# S1C31D01 register map
Vendor: Epson; Series: S1C31D01; File version: 1.00
CPU: CM0PLUS r0p1, little endian, MPU, no FPU, VTOR, 2 interrupt priority bits
Registers are 16-bit, read-write, reset 0x0 unless marked. A register's access mark holds for its fields unless they carry their own. Offsets are from the block's base; [hi:lo] are bit positions; {n}, {i} and the like mark numbered series; 'fields as' and 'values as' point back to an identical list.

## FLASHC — Flash controller
Base 0x400001B0
0x00 WAIT reset 0x1 — Flash Read Cycle Register
  [1:0] RDWAIT — RdCycle Number of cycles (can be write protected)

## UPMUX — Universal port multiplexer control
Base 0x40000300
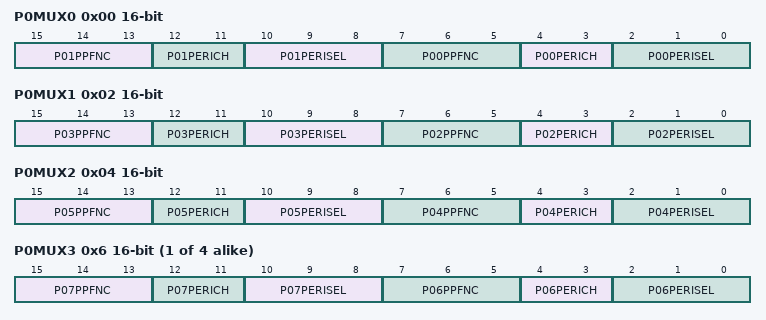
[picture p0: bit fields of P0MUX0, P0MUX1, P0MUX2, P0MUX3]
0x00 P0MUX0 — P00_01 Universal Port Multiplexer Setting Register
  [15:13] P01PPFNC — Assign pin function
  [12:11] P01PERICH — Assign Peripheral channel
  [10:8] P01PERISEL — Assign peripheral
  [7:5] P00PPFNC — Assign pin function
  [4:3] P00PERICH — Assign Peripheral channel
  [2:0] P00PERISEL — Assign peripheral
0x02 P0MUX1 — P02_03 Universal Port Multiplexer Setting Register
  [15:13] P03PPFNC — Assign pin function
  [12:11] P03PERICH — Assign peripheral channel
  [10:8] P03PERISEL — Assign peripheral
  [7:5] P02PPFNC — Assign pin function
  [4:3] P02PERICH — Assign Peripheral channel
  [2:0] P02PERISEL — Assign peripheral
0x04 P0MUX2 — P04_05 Universal Port Multiplexer Setting Register
  [15:13] P05PPFNC — Assign pin function
  [12:11] P05PERICH — Assign Peripheral channel
  [10:8] P05PERISEL — Assign peripheral
  [7:5] P04PPFNC — Assign pin function
  [4:3] P04PERICH — Assign Peripheral channel
  [2:0] P04PERISEL — Assign peripheral
{0x6+8i} P{i}MUX3 (i=0..3) — P{10i+6:02}_{10i+7:02} Universal Port Multiplexer Setting Register
  [15:13] P{10i+7:02}PPFNC — Assign pin function
  [12:11] P{10i+7:02}PERICH — Assign Peripheral channel
  [10:8] P{10i+7:02}PERISEL — Assign peripheral
  [7:5] P{10i+6:02}PPFNC — Assign pin function
  [4:3] P{10i+6:02}PERICH — Assign Peripheral channel
  [2:0] P{10i+6:02}PERISEL — Assign peripheral
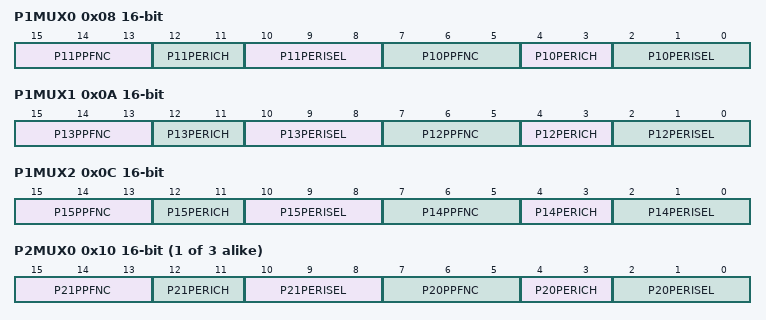
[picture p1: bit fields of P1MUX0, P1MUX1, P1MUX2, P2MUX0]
0x08 P1MUX0 — P10_11 Universal Port Multiplexer Setting Register
  [15:13] P11PPFNC — Assign pin function
  [12:11] P11PERICH — Assign Peripheral channel
  [10:8] P11PERISEL — Assign peripheral
  [7:5] P10PPFNC — Assign pin function
  [4:3] P10PERICH — Assign Peripheral channel
  [2:0] P10PERISEL — Assign peripheral
0x0A P1MUX1 — P12_13 Universal Port Multiplexer Setting Register
  [15:13] P13PPFNC — Assign pin function
  [12:11] P13PERICH — Assign Peripheral channel
  [10:8] P13PERISEL — Assign peripheral
  [7:5] P12PPFNC — Assign pin function
  [4:3] P12PERICH — Assign Peripheral channel
  [2:0] P12PERISEL — Assign peripheral
0x0C P1MUX2 — P14_15 Universal Port Multiplexer Setting Register
  [15:13] P15PPFNC — Assign pin function
  [12:11] P15PERICH — Assign Peripheral channel
  [10:8] P15PERISEL — Assign peripheral
  [7:5] P14PPFNC — Assign pin function
  [4:3] P14PERICH — Assign Peripheral channel
  [2:0] P14PERISEL — Assign peripheral
{0x10+2i} P2MUX{i} (i=0..2) — P{2i+20}_{2i+21} Universal Port Multiplexer Setting Register
  [15:13] P{2i+21}PPFNC — Assign pin function
  [12:11] P{2i+21}PERICH — Assign peripheral channel
  [10:8] P{2i+21}PERISEL — Assign peripheral
  [7:5] P{2i+20}PPFNC — Assign pin function
  [4:3] P{2i+20}PERICH — Assign peripheral channel
  [2:0] P{2i+20}PERISEL — Assign peripheral
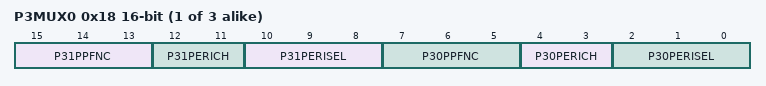
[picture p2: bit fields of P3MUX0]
{0x18+2i} P3MUX{i} (i=0..2) — P{2i+30}_{2i+31} Universal Port Multiplexer Setting Register
  [15:13] P{2i+31}PPFNC — Assign pin function
  [12:11] P{2i+31}PERICH — Assign peripheral channel
  [10:8] P{2i+31}PERISEL — Assign peripheral
  [7:5] P{2i+30}PPFNC — Assign pin function
  [4:3] P{2i+30}PERICH — Assign peripheral channel
  [2:0] P{2i+30}PERISEL — Assign peripheral

## UART3_0 — UART3 channel 0 control
Base 0x40000380
Same registers: UART3_1 0x40000600, UART3_2 0x40000620
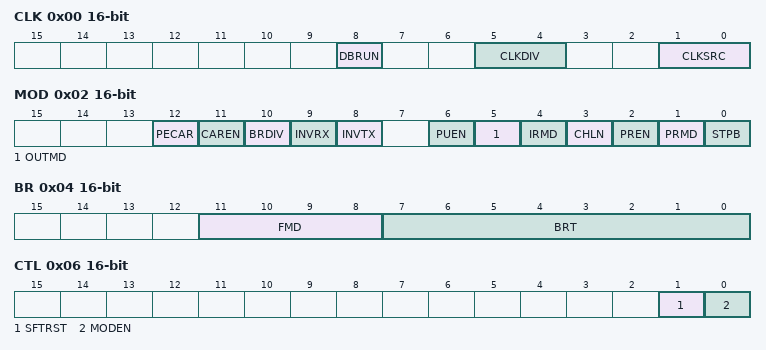
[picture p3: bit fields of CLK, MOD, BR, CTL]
0x00 CLK — Clock Control Register
  [8] DBRUN — Enable clock on debug mode
    0=DISABLE; 1=ENABLE
  [5:4] CLKDIV — Clock division select
  [1:0] CLKSRC — Clock source select (can be write protected)
    0=IOSC; 1=OSC1; 2=OSC3; 3=EXOSC
0x02 MOD — Mode Register
  [12] PECAR — Select carrier modulation
  [11] CAREN — Carrier modulation enable
  [10] BRDIV — Baud Rate Division ratio
    0=DIV_1_16 (Ratio 1 over 16); 1=DIV_1_4 (Ration 1 over 4)
  [9] INVRX — Invert receive signal
    0=DISABLE (Disable input inverting function); 1=ENABLE (Enable input inverting function)
  [8] INVTX — Invert transmit signal
    0=DISABLE (Disable output inverting function); 1=ENABLE (Enable output inverting function)
  [6] PUEN — USIN pullup enable
    0=DISABLE (Disable pull-up); 1=ENABLE (Enable pull-up)
  [5] OUTMD — Output mode select
    0=PUSH_PULL (Push-pull output); 1=OPEN_DRAIN (Open-drain output)
  [4] IRMD — IrDA mode select
    0=DISABLE (Disable IrDA interface function); 1=ENABLE (Enable IrDA interface function)
  [3] CHLN — Character length
    0=7_BIT (7 bits); 1=8_BIT (8 bits)
  [2] PREN — Parity enable
    0=DISABLE (Disable parity function); 1=ENABLE (Enable parity function)
  [1] PRMD — Parity mode select
    0=EVEN (Even parity); 1=ODD (Odd parity)
  [0] STPB — Stop bit select
    0=1_BIT; 1=2_BIT (2 bits)
0x04 BR — Baud Rate Register
  [11:8] FMD — Fine mode control
  [7:0] BRT — Baud rate setting
0x06 CTL — Control Register
  [1] SFTRST write-1-sets — Soft reset
    on write: 0=NON (No effect); 1=RESET (Issue software reset) | on read: 0=STOPPED (Software reset has finished (During normal operation)); 1=RUNNING (Software reset is executing)
  [0] MODEN — UART3 enable
    0=DISABLE (Disable UART2 operations (The operating clock is stopped)); 1=ENABLE (Enable UART2 operations (The operating clock is supplied))
0x08 TXD — Transmit Data Register
  [7:0] TXD — Transmit data
0x0A RXD ro — Receive Data Register
  [7:0] RXD — Receive data
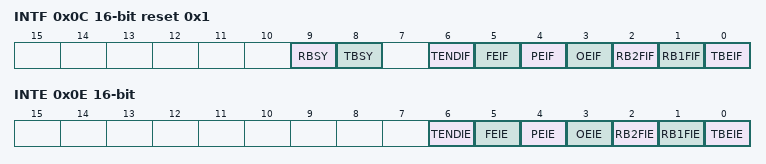
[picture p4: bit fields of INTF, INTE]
0x0C INTF reset 0x1 — Status and Interrupt Flag Register
  [9] RBSY ro — Receive busy status
    0=IDLE; 1=BUSY (During receiving)
  [8] TBSY ro — Transmit busy status
    0=IDLE; 1=BUSY (During sending)
  [6] TENDIF ro write-1-clears — End of transmission interrupt flag
    0=NOT_OCCURED (No cause of interrupt occurred); 1=OCCURED (Cause of interrupt occurred)
  [5] FEIF ro write-1-clears — Framing error interrupt flag
    values as TENDIF
  [4] PEIF ro write-1-clears — Parity error interrupt flag
    values as TENDIF
  [3] OEIF ro write-1-clears — Overrun error interrupt flag
    values as TENDIF
  [2] RB2FIF ro — Receive buffer 2byte full interrupt flag
    values as TENDIF
  [1] RB1FIF ro — Receive buffer 1byte full interrupt flag
    values as TENDIF
  [0] TBEIF ro — Transmit buffer empty interrupt flag
    values as TENDIF
0x0E INTE — Interrupt Enable Register
  [all] fields
    0=DISABLE; 1=ENABLE
  [6] TENDIE — End of transmission interrupt enable
  [5] FEIE — Framing error interrupt enable
  [4] PEIE — Parity error interrupt enable
  [3] OEIE — Overrun error interrupt enable
  [2] RB2FIE — Receive buffer 2byte full interrupt enable
  [1] RB1FIE — Receive buffer 1byte full interrupt enable
  [0] TBEIE — Transmit buffer empty interrupt enable
0x10 TBEDMAEN — TBE DMA Enable Register
  [3:0] TBEDMAEN — TBE DMA ch0 request enable
0x12 RB1FDMAEN — RB1F DMA Enable Register
  [3:0] RB1FDMAEN — RB1F DMA ch0 request enable
0x14 CAWF — UART carrier waveform register
  [7:0] CRPER — Carrier period
